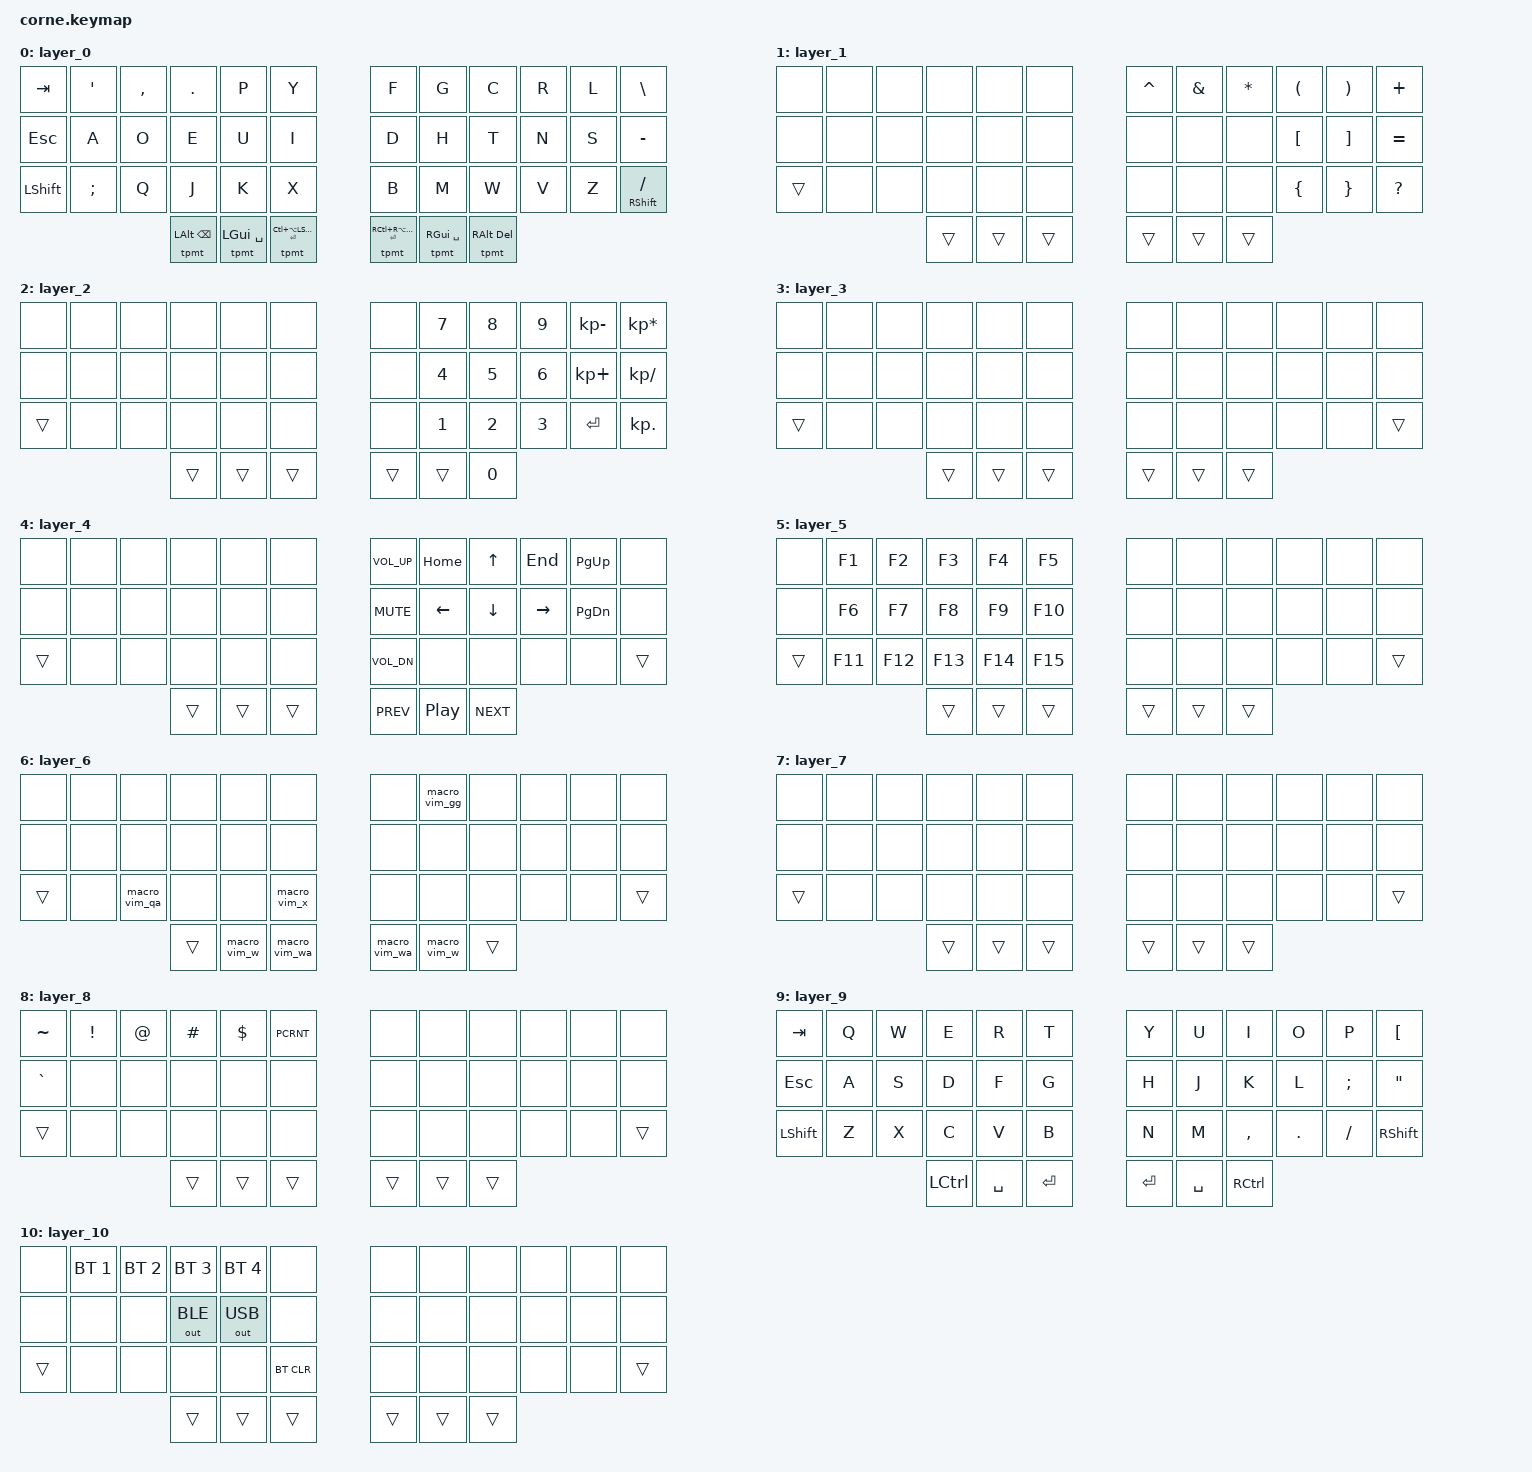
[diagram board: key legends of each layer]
// vim: set ft=devicetree sw=4 ts=4 sts=4 expandtab :
//
// Copyright (c) 2020 The ZMK Contributors
//
// SPDX-License-Identifier: MIT
//
// vim tabularize command: (works in normal or visual line modes)
//     Tabularize / &/l0
//
// Usage Notes:
//  - layer 9 can be accessed by layer taps on F and Y for ergonomics and
//  troubleshooting.
//  - device switching is done by F or Y, and keys on the left-hand top row
//  starting wih 0, so that 1 is directly
//    above the left pinky finger.
//  - clearing a device is done by holding F or Y, and then tapping X.
//  - output selection is done by holding F or Y and then tapping U for USB, E
//  for BLE.

#include <behaviors.dtsi>
#include <dt-bindings/zmk/bt.h>
#include <dt-bindings/zmk/keys.h>

// {
	behaviors {
        tpmt
            tap_preferred_mod_tap {
                compatible = "zmk,behavior-hold-tap";
                label = "TPMT";
                tapping-term-ms = <150>;
                quick-tap-ms = <0>;
                flavor = "tap-preferred";
                bindings = <&kp>, <&kp>;
            };
	};
	combos {
		compatible = "zmk,combos";
		combo_lctrl {
			bindings = <&kp LCTRL>;
			key-positions = <16 17>;
			slow-release;
			timeout-ms = <50>;
		};
		combo_rctrl {
			bindings = <&kp RCTRL>;
			key-positions = <18 19>;
			slow-release;
			timeout-ms = <50>;
		};
		combo_layer_1 {
			bindings = <&mo 1>;
			key-positions = <12 13>;
			slow-release;
			timeout-ms = <50>;
		};
		combo_layer_2 {
			bindings = <&mo 2>;
			key-positions = <13 14>;
			slow-release;
			timeout-ms = <50>;
		};
		combo_layer_3 {
			bindings = <&mo 3>;
			key-positions = <14 15>;
			slow-release;
			timeout-ms = <50>;
		};
		combo_layer_4 {
			bindings = <&mo 4>;
			key-positions = <15 16>;
			slow-release;
			timeout-ms = <50>;
		};
		combo_layer_5 {
			bindings = <&mo 5>;
			key-positions = <22 23>;
			slow-release;
			timeout-ms = <50>;
		};
		combo_layer_6 {
			bindings = <&mo 6>;
			key-positions = <21 22>;
			slow-release;
			timeout-ms = <50>;
		};
		combo_layer_7 {
			bindings = <&mo 7>;
			key-positions = <20 21>;
			slow-release;
			timeout-ms = <50>;
		};
		combo_layer_8 {
			bindings = <&mo 8>;
			key-positions = <19 20>;
			slow-release;
			timeout-ms = <50>;
		};
		combo_layer_9 {
			bindings = <&tog 9>;
			key-positions = <26 27>;
			slow-release;
			timeout-ms = <50>;
		};
		combo_layer_10 {
			bindings = <&mo 10>;
			key-positions = <6 7>;
			slow-release;
			timeout-ms = <50>;
		};
	};
	macros {
        macro_vim_gg:
            macro_vim_gg {
                compatible = "zmk,behavior-macro";
                bindings = <&kp ESC &kp G &kp G &kp EQUAL &kp LS(G)>;
            };
        macro_vim_x:
            macro_vim_x {
                compatible = "zmk,behavior-macro";
                bindings = <&kp ESC &kp COLON &kp X &kp ENTER>;
            };
        macro_vim_w:
           macro_vim_w {
               compatible = "zmk,behavior-macro";
               bindings = <&kp ESC &kp COLON &kp W &kp ENTER>;
           };
        macro_vim_wa:
            macro_vim_wa {
                compatible = "zmk,behavior-macro";
                bindings = <&kp ESC &kp COLON &kp W &kp A &kp ENTER>;
            };
        macro_vim_qa_bang:
            macro_vim_qa_bang {
                compatible = "zmk,behavior-macro";
                bindings = <&kp ESC &kp COLON &kp Q &kp A &kp EXCLAMATION &kp ENTER>;
            };
	};
	keymap {
		compatible = "zmk,keymap";
		layer_0 {
			bindings = < 
				&kp TAB &kp SQT &kp COMMA &kp DOT &kp P &kp Y &kp F &kp G &kp C &kp R &kp L &kp BSLH
				&kp ESC &kp A &kp O &kp E &kp U &kp I &kp D &kp H &kp T &kp N &kp S &kp MINUS
				&kp LSHFT &kp SEMI &kp Q &kp J &kp K &kp X &kp B &kp M &kp W &kp V &kp Z &mt RSHFT FSLH
				&tpmt LALT BSPC &tpmt LGUI SPACE &tpmt LC(LA(LSHIFT)) RET &tpmt RC(RA(RSHIFT)) RET &tpmt RGUI SPACE &tpmt RALT DEL
				>;
		};
		layer_1 {
			bindings = < 
				&none &none &none &none &none &none &kp CARET &kp AMPS &kp ASTRK &kp LPAR &kp RPAR &kp PLUS
				&none &none &none &none &none &none &none &none &none &kp LBKT &kp RBKT &kp EQUAL
				&trans &none &none &none &none &none &none &none &none &kp LBRC &kp RBRC &kp QUESTION
				&trans &trans &trans &trans &trans &trans
				>;
		};
		layer_2 {
			bindings = < 
				&none &none &none &none &none &none &none &kp N7 &kp N8 &kp N9 &kp KP_MINUS &kp KP_ASTERISK
				&none &none &none &none &none &none &none &kp N4 &kp N5 &kp N6 &kp KP_PLUS &kp KP_SLASH
				&trans &none &none &none &none &none &none &kp N1 &kp N2 &kp N3 &kp RETURN &kp KP_DOT
				&trans &trans &trans &trans &trans &kp N0
				>;
		};
		layer_3 {
			bindings = < 
				&none &none &none &none &none &none &none &none &none &none &none &none
				&none &none &none &none &none &none &none &none &none &none &none &none
				&trans &none &none &none &none &none &none &none &none &none &none &trans
				&trans &trans &trans &trans &trans &trans
				>;
		};
		layer_4 {
			bindings = < 
				&none &none &none &none &none &none &kp C_VOL_UP &kp HOME &kp UP &kp END &kp PG_UP &none
				&none &none &none &none &none &none &kp C_MUTE &kp LEFT &kp DOWN &kp RIGHT &kp PG_DN &none
				&trans &none &none &none &none &none &kp C_VOL_DN &none &none &none &none &trans
				&trans &trans &trans &kp C_PREV &kp C_PP &kp C_NEXT
				>;
		};
		layer_5 {
			bindings = < 
				&none &kp F1 &kp F2 &kp F3 &kp F4 &kp F5 &none &none &none &none &none &none
				&none &kp F6 &kp F7 &kp F8 &kp F9 &kp F10 &none &none &none &none &none &none
				&trans &kp F11 &kp F12 &kp F13 &kp F14 &kp F15 &none &none &none &none &none &trans
				&trans &trans &trans &trans &trans &trans
				>;
		};
		layer_6 {
			bindings = < 
				&none &none &none &none &none &none &none &macro_vim_gg &none &none &none &none
				&none &none &none &none &none &none &none &none &none &none &none &none
				&trans &none &macro_vim_qa &none &none &macro_vim_x &none &none &none &none &none &trans
				&trans &macro_vim_w &macro_vim_wa &macro_vim_wa &macro_vim_w &trans
				>;
		};
		layer_7 {
			bindings = < 
				&none &none &none &none &none &none &none &none &none &none &none &none
				&none &none &none &none &none &none &none &none &none &none &none &none
				&trans &none &none &none &none &none &none &none &none &none &none &trans
				&trans &trans &trans &trans &trans &trans
				>;
		};
		layer_8 {
			bindings = < 
				&kp TILDE &kp EXCL &kp AT &kp HASH &kp DLLR &kp PCRNT &none &none &none &none &none &none
				&kp GRAVE &none &none &none &none &none &none &none &none &none &none &none
				&trans &none &none &none &none &none &none &none &none &none &none &trans
				&trans &trans &trans &trans &trans &trans
				>;
		};
		layer_9 {
			bindings = < 
				&kp TAB &kp Q &kp W &kp E &kp R &kp T &kp Y &kp U &kp I &kp O &kp P &kp LBKT
				&kp ESC &kp A &kp S &kp D &kp F &kp G &kp H &kp J &kp K &kp L &kp SEMI &kp DQT
				&kp LSHFT &kp Z &kp X &kp C &kp V &kp B &kp N &kp M &kp COMMA &kp DOT &kp FSLH &kp RSHFT
				&kp LCTRL &kp SPACE &kp RET &kp RET &kp SPACE &kp RCTRL
				>;
		};
		layer_10 {
			bindings = < 
				&none &bt BT_SEL 1 &bt BT_SEL 2 &bt BT_SEL 3 &bt BT_SEL 4 &none &none &none &none &none &none &none
				&none &none &none &out OUT_BLE &out OUT_USB &none &none &none &none &none &none &none
				&trans &none &none &none &none &bt BT_CLR &none &none &none &none &none &trans
				&trans &trans &trans &trans &trans &trans
				>;
		};
	};
};
